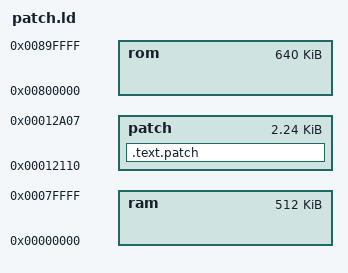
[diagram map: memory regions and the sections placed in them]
MEMORY
{
    ram : ORIGIN = 0x0, LENGTH = 512K
    rom : ORIGIN = 0x800000, LENGTH = 640K
    /* override wlc_recvdata */
    patch : ORIGIN = 0x12110, LENGTH = 2296
}

SECTIONS
{
    /* include the patch.generated.ld file that was generated by the nexmon gcc plugin after evaluating the "at" attributes */
    INCLUDE patch.generated.ld
    INCLUDE wrapper.generated.ld
    INCLUDE flashpatch.generated.ld

	.text.patch : { patch.o (.text .text.* .data .data.* .bss .bss.* .rodata .rodata.*) } >patch
}
